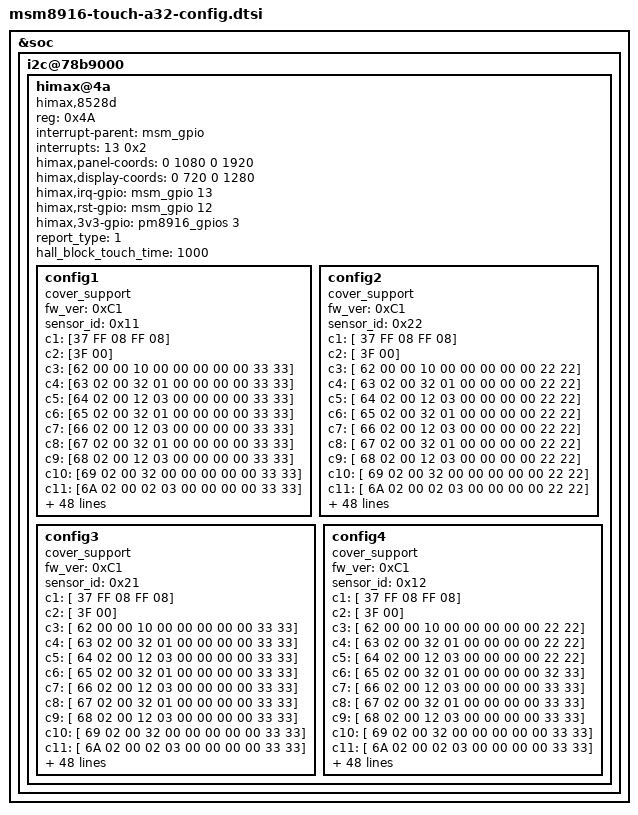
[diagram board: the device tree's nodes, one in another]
&soc {
	i2c@78b9000 { /* BLSP1 QUP5 */
		himax@4a {
			compatible		= "himax,8528d";
			reg			= <0x4A>;
			interrupt-parent	= <&msm_gpio>;
			interrupts		= <13 0x2>;
			himax,panel-coords	= <0 1080 0 1920>;
			himax,display-coords	= <0 720 0 1280>;
			himax,irq-gpio		= <&msm_gpio 13 0x00>;
			himax,rst-gpio		= <&msm_gpio 12 0x00>;
			himax,3v3-gpio		= <&pm8916_gpios 3 0x00>;
			report_type		= <1>;
			hall_block_touch_time	= <1000>;	/* msec */

			config1 {	//HH sensor_id = 0x21
				cover_support;
				fw_ver     	= <0xC1>;
				sensor_id     	= <0x11>;
				c1 = [37 FF 08 FF 08];
				c2 = [3F 00];
				c3 = [62 00 00 10 00 00 00 00 00 33 33];
				c4 = [63 02 00 32 01 00 00 00 00 33 33];
				c5 = [64 02 00 12 03 00 00 00 00 33 33];
				c6 = [65 02 00 32 01 00 00 00 00 33 33];
				c7 = [66 02 00 12 03 00 00 00 00 33 33];
				c8 = [67 02 00 32 01 00 00 00 00 33 33];
				c9 = [68 02 00 12 03 00 00 00 00 33 33];
				c10 = [69 02 00 32 00 00 00 00 00 33 33];
				c11 = [6A 02 00 02 03 00 00 00 00 33 33];
				c12 = [6B 02 00 32 01 00 00 00 00 00 00];
				c13 = [6C 02 00 12 03 00 00 00 00 00 00];
				c14 = [6D 02 00 02 01 00 00 00 00 00 00];
				c15 = [6E 02 00 12 00 00 00 00 00 00 00];
				c16 = [6F 02 00 02 01 00 00 00 00 00 00];
				c17 = [70 00 00 30 00 00 00 00 00 00 00];
				c18 = [7B 03];
				c19 = [7C 00 D8 0C];
				c20 = [7F 00 04 0A 0A 04 00 00 00];
				c21 = [A4 94 62 94 86];
				c22 = [B4 06 01 02 02 02 03 07 03 0F 03 0F 03 0F 08];
				c23 = [B9 01 36];
				c24 = [BA 00];
				c25 = [BB 00];
				c26 = [BC 00 00 00 00];
				c27 = [BD 04 0C];
				c28 = [C2 10 00 00 00 00 00 00 00];
				c29 = [C5 0A 1C 00 10 1A 1E 0B 1C 08 16];
				c30 = [C6 16 10 17];
				c31 = [C9 00 00 00 07 01 03 05 0B 0D 2D 28 26 24 22 20 06 02 04 0A 0C 0E 29 27 25 23 21 00 00 00 00 00
					   00 00 00 00 00 00 00 00 00 00 00 00 00 00 00 00 00 00 00 00 00 00 00 00 00 00 00 00 00 00 00 00 00];
				c32 = [CB 01 F5 FF FF 01 00 05 00 9F 00 00 00];
				c33 = [D0 06 01];
				c34 = [D3 06 01];
				c35 = [D5 29 00 00 00 00 00 00 00 00 00 00 00 00 00 00 00];
				c36 = [40 04 5A 5F 00 F2 10 00 00 30 0C 0A 10 09 09 0C 0F 0F 0F 30 2E 40 40 50 00 00 00 00 00 00 00];
				c37 = [40 94 0A F0 83 85 00 44 22 0F 0F 83 3C 00 00 11 00 41 42 1F 3F 00 12 00 00 10 01 3C 64 00 00];
				c38 = [40 28 37 37 05 1F 00 00 00 04 06 24 06 06 00 00 00];
				c39 = [40 24 1C 05 02 00 D8 0C 00 00 02 03 00 00 00 00 00 10 02 80 00 00 00 00 0C];
				c40 = [40 00 00 00 00 00 00 00 00 AA 6E 32 01 0D 17 A0 13 00 00 04 38 07 80];
				c41 = [40 05 AB 0C C0 65 56 08 00 DB 03 89 5C CC 0A 07 3F 10 4F 6A 39 00 01 2D 04 DB 60 22 00];
				c42 = [40 00 00 00 00 00 00 00 00];
				c43_1 = [40 0F FF FF FF 10 00 23 FF 11 01 22 FF 12 02 21 FF 13 03 20 FF 0E 04 1F FF 0D 05 1E FF FF 06 1D];
				c43_2 = [40 FF FF 07 1C FF 14 08 1B FF 15 09 1A FF 16 0A FF FF 17 0B FF FF 18 0C FF FF FF FF 19 FF];
				c44_1 = [40 33 00 C0 00 19 0A 28 00 00 00 00 00 00 00 00 00 00 00 00 00 11 C4 45 C5 48 5C 03 00 00 00 5C];
				c44_2 = [40 03 11 03 05 18];
				c45   = [40 00 00];
			};

			config2 {	//Truly sensor_id = 0x22
				cover_support;
				fw_ver     	= <0xC1>;
				sensor_id     	= <0x22>;
				c1 = [ 37 FF 08 FF 08];
				c2 = [ 3F 00];
				c3 = [ 62 00 00 10 00 00 00 00 00 22 22];
				c4 = [ 63 02 00 32 01 00 00 00 00 22 22];
				c5 = [ 64 02 00 12 03 00 00 00 00 22 22];
				c6 = [ 65 02 00 32 01 00 00 00 00 22 22];
				c7 = [ 66 02 00 12 03 00 00 00 00 22 22];
				c8 = [ 67 02 00 32 01 00 00 00 00 22 22];
				c9 = [ 68 02 00 12 03 00 00 00 00 22 22];
				c10 = [ 69 02 00 32 00 00 00 00 00 22 22];
				c11 = [ 6A 02 00 02 03 00 00 00 00 22 22];
				c12 = [ 6B 02 00 32 01 00 00 00 00 00 00];
				c13 = [ 6C 02 00 12 03 00 00 00 00 00 00];
				c14 = [ 6D 02 00 02 01 00 00 00 00 00 00];
				c15 = [ 6E 02 00 12 00 00 00 00 00 00 00];
				c16 = [ 6F 02 00 02 01 00 00 00 00 00 00];
				c17 = [ 70 00 00 30 00 00 00 00 00 00 00];
				c18 = [ 7B 03];
				c19 = [ 7C 00 D8 0C];
				c20 = [ 7F 00 04 0A 0A 04 00 00 00];
				c21 = [ A4 94 62 94 86];
				c22 = [ B4 06 01 02 02 02 03 07 03 0F 03 0F 03 0F 08];
				c23 = [ B9 01 36];
				c24 = [ BA 00];
				c25 = [ BB 00];
				c26 = [ BC 00 00 00 00];
				c27 = [ BD 04 0C];
				c28 = [ C2 10 00 00 00 00 00 00 00];
				c29 = [ C5 0A 1E 00 10 1B 1E 0B 1E 08 16];
				c30 = [ C6 1A 10 1A];
				c31 = [ C9 00 00 00 07 01 03 05 0B 0D 2D 28 26 24 22 20 06 02 04 0A 0C 0E 29 27 25 23 21 00 00 00 00 00 00
					00 00 00 00 00 00 00 00 00 00 00 00 00 00 00 00 00 00 00 00 00 00 00 00 00 00 00 00 00 00 00 00];
				c32 = [ CB 01 F5 FF FF 01 00 05 00 9F 00 00 00];
				c33 = [ D0 06 01];
				c34 = [ D3 06 01];
				c35 = [ D5 29 00 00 00 00 00 00 00 00 00 00 00 00 00 00 00];
				c36 = [ 40 22 5A 5F 00 F2 10 00 00 37 0E 0A 10 09 09 0C 0F 0F 0F 30 2E 40 40 50 00 00 00 00 00 00 00];
				c37 = [ 40 94 0A F0 82 85 00 49 27 0F 0F 83 3C 00 00 11 00 41 42 28 38 00 18 00 00 10 01 3C 64 00 00];
				c38 = [ 40 20 37 37 08 1F 00 00 00 04 06 24 06 06 00 00 00];
				c39 = [ 40 24 1C 05 02 00 D8 0C 00 00 02 03 00 00 00 00 00 10 02 80 00 00 00 00 0C];
				c40 = [ 40 00 00 00 00 00 00 00 00 BE 6E 32 00 0D 17 A0 13 00 00 04 38 07 80];
				c41 = [ 40 05 AB 0C C0 65 56 08 00 DB 03 89 5C CC 0A 07 3F 10 4F 6A 39 00 01 2D 04 DB 60 22 00];
				c42 = [ 40 00 00 00 00 00 00 00 00];
				c43_1 = [ 40 0F FF FF FF 10 00 23 FF 11 01 22 FF 12 02 21 FF 13 03 20 FF 0E 04 1F FF 0D 05 1E FF FF 06 1D];
				c43_2 = [ 40 FF FF 07 1C FF 14 08 1B FF 15 09 1A FF 16 0A FF FF 17 0B FF FF 18 0C FF FF FF FF 19 FF];
				c44_1 = [ 40 33 00 C0 00 19 0A 28 00 00 00 00 00 00 00 00 00 00 00 00 00 11 C4 45 C5 48 5C 03 00 00 00 5C];
				c44_2 = [ 40 03 11 03 05 18];
				c45   = [ 40 00 00];
			};

			config3 {	//HH sensor_id = 0x21
				cover_support;
				fw_ver     	= <0xC1>;
				sensor_id     	= <0x21>;
				c1 = [ 37 FF 08 FF 08];
				c2 = [ 3F 00];
				c3 = [ 62 00 00 10 00 00 00 00 00 33 33];
				c4 = [ 63 02 00 32 01 00 00 00 00 33 33];
				c5 = [ 64 02 00 12 03 00 00 00 00 33 33];
				c6 = [ 65 02 00 32 01 00 00 00 00 33 33];
				c7 = [ 66 02 00 12 03 00 00 00 00 33 33];
				c8 = [ 67 02 00 32 01 00 00 00 00 33 33];
				c9 = [ 68 02 00 12 03 00 00 00 00 33 33];
				c10 = [ 69 02 00 32 00 00 00 00 00 33 33];
				c11 = [ 6A 02 00 02 03 00 00 00 00 33 33];
				c12 = [ 6B 02 00 32 01 00 00 00 00 00 00];
				c13 = [ 6C 02 00 12 03 00 00 00 00 00 00];
				c14 = [ 6D 02 00 02 01 00 00 00 00 00 00];
				c15 = [ 6E 02 00 12 00 00 00 00 00 00 00];
				c16 = [ 6F 02 00 02 01 00 00 00 00 00 00];
				c17 = [ 70 00 00 30 00 00 00 00 00 00 00];
				c18 = [ 7B 03];
				c19 = [ 7C 00 D8 0C];
				c20 = [ 7F 00 04 0A 0A 04 00 00 00];
				c21 = [ A4 94 62 94 86];
				c22 = [ B4 06 01 02 02 02 03 07 03 0F 03
					0F 03 0F 08];
				c23 = [ B9 01 36];
				c24 = [ BA 00];
				c25 = [ BB 00];
				c26 = [ BC 00 00 00 00];
				c27 = [ BD 04 0C];
				c28 = [ C2 10 00 00 00 00 00 00 00];
				c29 = [ C5 0A 1C 00 10 1A 1E 0B 1C 08 16];
				c30 = [ C6 16 10 17];
				c31 = [ C9 00 00 00 07 01 03 05 0B 0D 2D
					28 26 24 22 20 06 02 04 0A 0C
					0E 29 27 25 23 21 00 00 00 00
					00 00 00 00 00 00 00 00 00 00
					00 00 00 00 00 00 00 00 00 00
					00 00 00 00 00 00 00 00 00 00
					00 00 00 00];
				c32 = [ CB 01 F5 FF FF 01 00 05 00 9F 00
					00 00];
				c33 = [ D0 06 01];
				c34 = [ D3 06 01];
				c35 = [ D5 29 00 00 00 00 00 00 00 00 00
					00 00 00 00 00 00];
				c36 = [ 40 04 5A
					5F 00 F2 10 00 00
					30 0C 0A 10 09 09 0C 0F 0F 0F
					30 2E 40 40 50 00 00 00 00 00
					00 00];
				c37 = [ 40 94 0A F0 82 85 00
					44 22 0F 0F 83 3C 00 00
					11 00 41 42
					1F 3F 00 12 00 00
					10 01 3C 64 00 00];
				c38 = [ 40 28 37 37 05 1F 00 00 00
					04 06 24 06 06 00 00 00];
				c39 = [ 40 24 1C 05 02 00 D8 0C 00 00 02
					03 00 00 00 00 00
					10 02 80 00 00 00 00 0C];
				c40 = [ 40 00 00 00 00 00 00 00 00
					AA 6E 32 01
					0D 17 A0 13
					00 00 04 38 07 80];
				c41 = [ 40 05 AB 0C C0 65 56 08 00 DB 03
					89 5C CC 0A
					07 3F 10 4F 6A 39 00 01 2D 04
					DB 60 22 00];
				c42 = [ 40 00 00 00 00 00 00 00 00];
				c43_1=[ 40 0F FF FF FF 10 00 23 FF 11 01
					22 FF 12 02 21 FF 13 03 20 FF
					0E 04 1F FF 0D 05 1E FF FF 06
					1D];
				c43_2=[ 40 FF FF 07 1C FF 14 08 1B FF
					15 09 1A FF 16 0A FF FF 17 0B
					FF FF 18 0C FF FF FF FF 19 FF];
				c44_1=[ 40 33 00 C0 00 19 0A 28 00 00 00
					00 00 00 00 00 00 00 00 00 00
					11 C4 45 C5 48 5C 03 00 00 00
					5C];
				c44_2=[ 40 03 11 03 05 18];
				c45 = [ 40 00 00];
			};

			config4 {	//HH sensor_id = 0x21
				cover_support;
				fw_ver     	= <0xC1>;
				sensor_id     	= <0x12>;
				c1 = [ 37 FF 08 FF 08];
				c2 = [ 3F 00];
				c3 = [ 62 00 00 10 00 00 00 00 00 22 22];
				c4 = [ 63 02 00 32 01 00 00 00 00 22 22];
				c5 = [ 64 02 00 12 03 00 00 00 00 22 22];
				c6 = [ 65 02 00 32 01 00 00 00 00 32 33];
				c7 = [ 66 02 00 12 03 00 00 00 00 33 33];
				c8 = [ 67 02 00 32 01 00 00 00 00 33 33];
				c9 = [ 68 02 00 12 03 00 00 00 00 33 33];
				c10 = [ 69 02 00 32 00 00 00 00 00 33 33];
				c11 = [ 6A 02 00 02 03 00 00 00 00 33 33];
				c12 = [ 6B 02 00 32 01 00 00 00 00 00 00];
				c13 = [ 6C 02 00 12 03 00 00 00 00 00 00];
				c14 = [ 6D 02 00 02 01 00 00 00 00 00 00];
				c15 = [ 6E 02 00 12 00 00 00 00 00 00 00];
				c16 = [ 6F 02 00 02 01 00 00 00 00 00 00];
				c17 = [ 70 00 00 30 00 00 00 00 00 00 00];
				c18 = [ 7B 03];
				c19 = [ 7C 00 D8 0C];
				c20 = [ 7F 00 04 0A 0A 04 00 00 00];
				c21 = [ A4 94 62 94 86];
				c22 = [ B4 06 01 02 02 02 03 07 03 0F 03 0F 03 0F 08];
				c23 = [ B9 01 36];
				c24 = [ BA 00];
				c25 = [ BB 00];
				c26 = [ BC 00 00 00 00];
				c27 = [ BD 04 0C];
				c28 = [ C2 10 00 00 00 00 00 00 00];
				c29 = [ C5 0A 1A 00 10 1B 1E 0B 1A 08 16];
				c30 = [ C6 18 10 1A];
				c31 = [ C9 00 00 00 07 01 03 05 0B 0D 2D 28 26 24 22 20 06 02 04 0A 0C 0E 29 27 25 23 21 00 00 00 00 00 00
					00 00 00 00 00 00 00 00 00 00 00 00 00 00 00 00 00 00 00 00 00 00 00 00 00 00 00 00 00 00 00 00];
				c32 = [ CB 01 F5 FF FF 01 00 05 00 9F 00 00 00];
				c33 = [ D0 06 01];
				c34 = [ D3 06 01];
				c35 = [ D5 29 00 00 00 00 00 00 00 00 00 00 00 00 00 00 00];
				c36 = [ 40 41 5A 5F 00 F2 10 00 00 3C 0E 0A 10 09 09 0C 0F 0F 0F 30 2E 40 40 50 00 00 00 00 00 00 00];
				c37 = [ 40 94 0A F0 82 85 00 49 27 0F 0F 83 3C 00 00 11 00 41 42 28 38 00 1C 00 00 10 01 3C 64 00 00];
				c38 = [ 40 20 37 37 08 1F 00 00 00 04 06 24 06 06 00 00 00];
				c39 = [ 40 24 1C 05 02 00 D8 0C 00 00 02 03 00 00 00 00 00 10 02 80 00 00 00 00 0C];
				c40 = [ 40 00 00 00 00 00 00 00 00 C8 6E 32 00 0D 17 A0 13 00 00 04 38 07 80];
				c41 = [ 40 05 FE 0D 7C 66 11 08 00 BC 03 06 5B DC 0A 07 93 11 0A 6A F5 00 01 0E 04 58 5F 31 00];
				c42 = [ 40 00 00 00 00 00 00 00 00];
				c43_1 = [ 40 0F FF FF FF 10 00 23 FF 11 01 22 FF 12 02 21 FF 13 03 20 FF 0E 04 1F FF 0D 05 1E FF FF 06 1D];
				c43_2 = [ 40 FF FF 07 1C FF 14 08 1B FF 15 09 1A FF 16 0A FF FF 17 0B FF FF 18 0C FF FF FF FF 19 FF];
				c44_1 = [ 40 33 00 C0 00 19 0A 28 00 00 00 00 00 00 00 00 00 00 00 00 00 11 C4 45 C5 48 5C 03 00 00 00 5C];
				c44_2 = [ 40 03 11 03 05 18];
				c45   = [ 40 00 00];
			};
		};
	};
};
